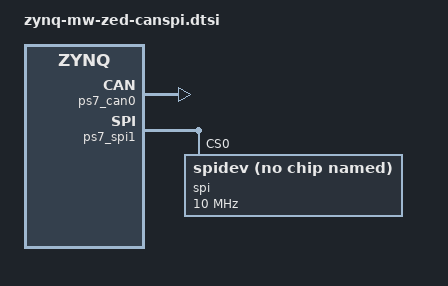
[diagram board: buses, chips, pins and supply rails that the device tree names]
/{

	amba@0 {
        
        ps7_can0: can@e0008000 {
            compatible = "xlnx,zynq-can-1.0";
            clocks = <&clkc 19>, <&clkc 36>;
            clock-names = "can_clk", "pclk";
            reg = <0xe0008000 0x1000>;
            interrupts = <0 28 4>;
            interrupt-parent = <&gic>;
            tx-fifo-depth = <0x40>;
            rx-fifo-depth = <0x40>;
        };

		ps7_spi1: spi@e0007000 {
            compatible = "cdns,spi-r1p6", "xlnx,ps7-spi-1.00.a";
			reg = <0xe0007000 0x1000>;
            #address-cells = <0x1>;
            #size-cells = <0x0>;
			interrupts = <0 49 4>;
			interrupt-parent = <&gic>;
            clock-names = "ref_clk", "aper_clk", "pclk";
            clocks = <&clkc 26>, <&clkc 35>, <&clkc 35>;
			speed-hz = <100000000>;
			bus-num = <0>;
			num-chip-select = <4>;
			xlnx,has-ss0 = <0x1>;
			xlnx,has-ss1 = <0x0>;
			xlnx,has-ss2 = <0x0>;
			xlnx,spi-clk-freq-hz = <0x5f5e100>;
			spi@0 {
				compatible = "spidev";
				reg = <0>;
				spi-max-frequency = <10000000>;
			};
		};		
    };
};

